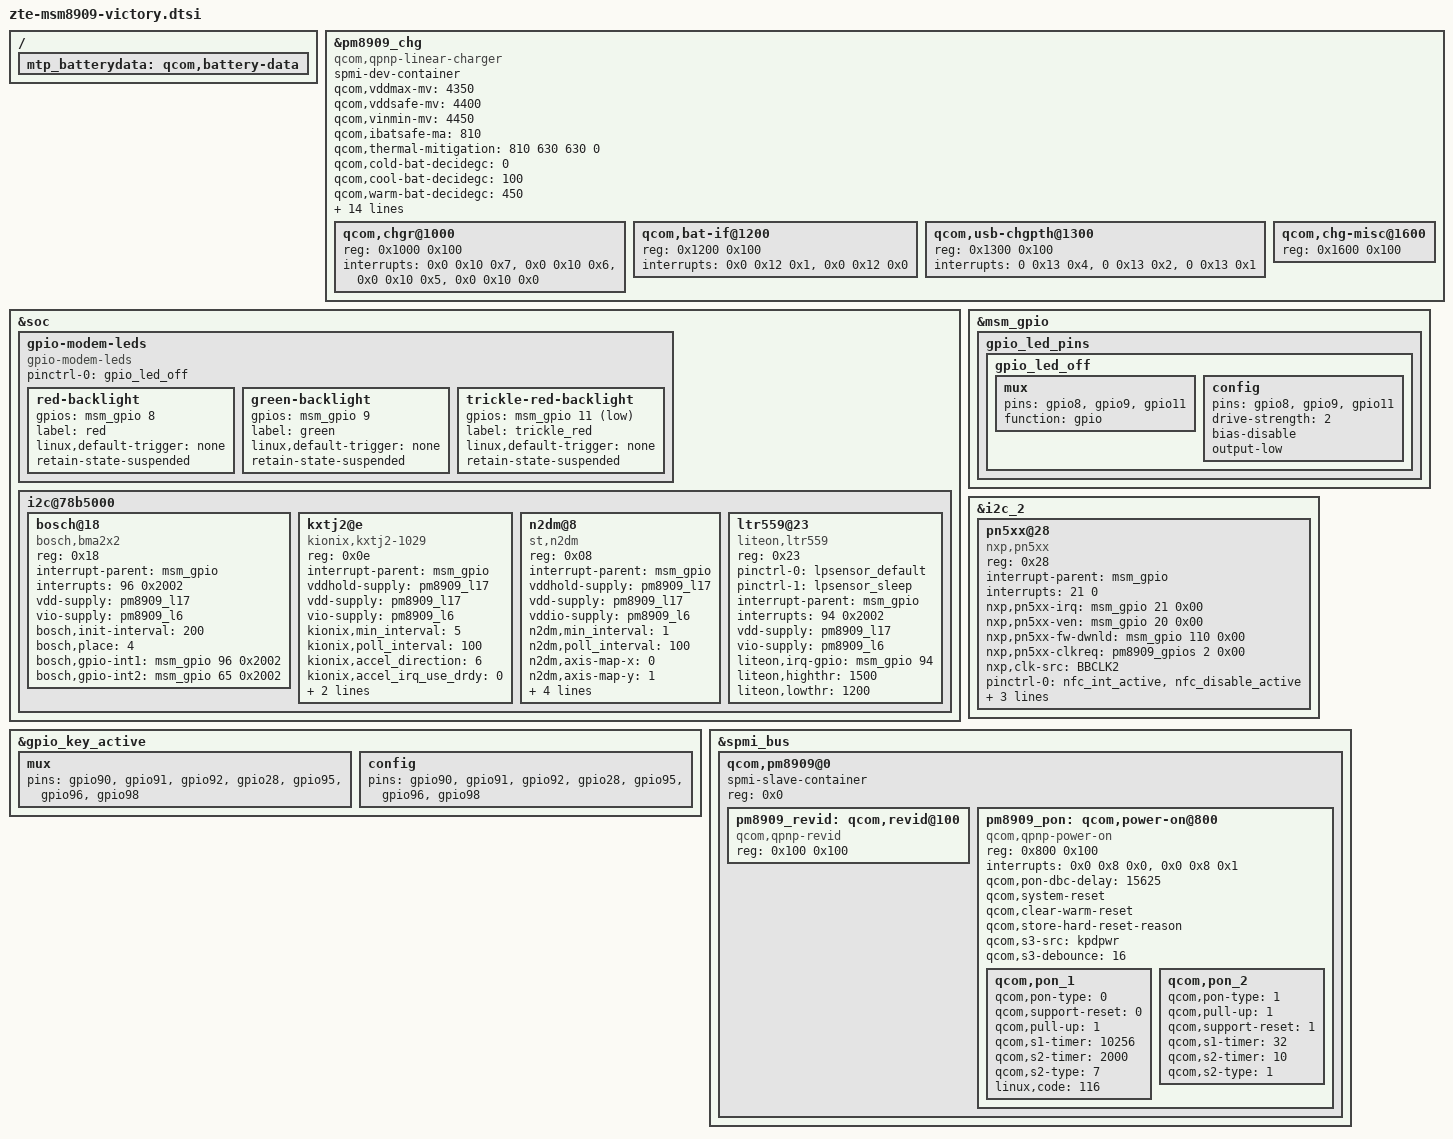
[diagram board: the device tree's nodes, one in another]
#include "touch-key-backlight-victory.dtsi"
#include "zte-victory-dsi-panel-jd9161b-holitech-480p-video.dtsi"
#include "zte-victory-dsi-panel-otm8019a-lianchuang-480p-video.dtsi"
&pm8909_chg {
	spmi-dev-container;
	compatible = "qcom,qpnp-linear-charger";
	#address-cells = <1>;
	#size-cells = <1>;

	qcom,vddmax-mv = <4350>;
	qcom,vddsafe-mv = <4400>;
	qcom,vinmin-mv = <4450>;
	qcom,ibatsafe-ma = <810>;
	qcom,thermal-mitigation = <810 630 630 0>;
	qcom,cold-bat-decidegc = <0>;
	qcom,cool-bat-decidegc = <100>;
	qcom,warm-bat-decidegc = <450>;
	qcom,hot-bat-decidegc = <600>;
	qcom,cool-bat-mv = <4350>;
	qcom,warm-bat-mv = <4100>;
	qcom,ibatmax-warm-ma = <450>;
	qcom,ibatmax-cool-ma = <630>;
	qcom,batt-hot-percentage = <25>;
	qcom,batt-cold-percentage = <80>;
	qcom,tchg-mins = <1536>;
	qcom,resume-soc = <97>;
	qcom,rpull-up-kohm = <100>;
	qcom,vref-batt-id = <1800000>;
	qcom,chg-vadc = <&pm8909_vadc>;
	qcom,chg-adc_tm = <&pm8909_adc_tm>;
	qcom,bpd-detection = "bpd_thm";
	/delete-property/qcom,disable-vbatdet-based-recharge;

	qcom,chgr@1000 {
		reg = <0x1000 0x100>;
		interrupts =	<0x0 0x10 0x7>,
				<0x0 0x10 0x6>,
				<0x0 0x10 0x5>,
				<0x0 0x10 0x0>;
		interrupt-names =	"chg-done",
					"chg-failed",
					"fast-chg-on",
					"vbat-det-lo";
	};

	qcom,bat-if@1200 {
		reg = <0x1200 0x100>;
		interrupts =	<0x0 0x12 0x1>,
				<0x0 0x12 0x0>;
		interrupt-names =	"bat-temp-ok",
					"batt-pres";
	};

	qcom,usb-chgpth@1300 {
		reg = <0x1300 0x100>;
		interrupts =	<0 0x13 0x4>,
				<0 0x13 0x2>,
				<0 0x13 0x1>;
		interrupt-names =	"usb-over-temp",
					"chg-gone",
					"usbin-valid";
	};

	qcom,chg-misc@1600 {
		reg = <0x1600 0x100>;
	};
};

/ {
	mtp_batterydata: qcom,battery-data {
		/delete-node/qcom,palladium-batterydata;
		#include "zte-byd-4v35-2200mah.dtsi"
		#include "zte-bak-4v35-2200mah.dtsi"
	};
};

&soc {
	/*ZTE_MODIFY, add leds gpio conrol, start*/
	gpio-modem-leds {
		compatible = "gpio-modem-leds";
		status = "okay";
		pinctrl-names = "default";
		pinctrl-0 = <&gpio_led_off>;

		red-backlight {
			gpios = <&msm_gpio 8 0>;
			label = "red";
			linux,default-trigger = "none";
			retain-state-suspended;
		};
		green-backlight {
			gpios = <&msm_gpio 9 0>;
			label = "green";
			linux,default-trigger = "none";
			retain-state-suspended;
		};
		trickle-red-backlight {
			gpios = <&msm_gpio 11 1>; /*active low*/
			label = "trickle_red";
			linux,default-trigger = "none";
			retain-state-suspended;
		};
	};
	/*ZTE_MODIFY, add leds gpio conrol, end*/

	i2c@78b5000 { /* BLSP1 QUP1 */
		bosch@18 { /* Accelerometer sensor */
			compatible = "bosch,bma2x2";
			reg = <0x18>;
			interrupt-parent = <&msm_gpio>;
			interrupts = <96 0x2002>;
			vdd-supply = <&pm8909_l17>;
			vio-supply = <&pm8909_l6>;
			bosch,init-interval = <200>;
			bosch,place = <4>;
			bosch,gpio-int1 = <&msm_gpio 96 0x2002>;
			bosch,gpio-int2 = <&msm_gpio 65 0x2002>;
		};

		kxtj2@e {
			compatible = "kionix,kxtj2-1029";
			reg = <0x0e>;
			interrupt-parent = <&msm_gpio>;
			/*interrupts = <96 0x2>;*/
			vddhold-supply = <&pm8909_l17>;
			vdd-supply = <&pm8909_l17>;
			vio-supply = <&pm8909_l6>;
			kionix,min_interval = <5>;
			kionix,poll_interval = <100>;
			kionix,accel_direction = <6>;
			kionix,accel_irq_use_drdy = <0>;
			/*0 is 12BIT,	1 is 8BIT,	2 is 6BIT*/
			kionix,accel_res = <0>;
			/*0 is 2g,	1 is 4g,	2 is 6g,	3 is 8g*/
			kionix,accel_g_range =	<0>;
		};

		n2dm@8 {
			compatible = "st,n2dm";
			reg = <0x08>;
			interrupt-parent = <&msm_gpio>;
			/*interrupts = <96 0x2>;*/
			vddhold-supply = <&pm8909_l17>;
			vdd-supply = <&pm8909_l17>;
			vddio-supply = <&pm8909_l6>;
			n2dm,min_interval = <1>;
			n2dm,poll_interval = <100>;
			n2dm,axis-map-x = <0>;
			n2dm,axis-map-y = <1>;
			n2dm,axis-map-z = <2>;
			n2dm,negate-x;
			/* n2dm,negate-y; */
			n2dm,negate-z;
			/*0 is 2g,	16 is 4g,	32 is 8g,	48 is 16g*/
			n2dm,fs-range = <0>;
		};

		ltr559@23 {
			compatible = "liteon,ltr559";
			reg = <0x23>;
			pinctrl-names = "lpsensor_default", "lpsensor_sleep";
			pinctrl-0 = <&lpsensor_default>;
			pinctrl-1 = <&lpsensor_sleep>;
			interrupt-parent = <&msm_gpio>;
			interrupts = <94 0x2002>;
			vdd-supply = <&pm8909_l17>;
			vio-supply = <&pm8909_l6>;
			liteon,irq-gpio = <&msm_gpio 94 0x2002>;
			liteon,highthr = <1500>;
			liteon,lowthr = <1200>;
		};

	};
};
&msm_gpio {
	/*ZTE_MODIFY, add leds gpio conrol, start*/
	gpio_led_pins {
		gpio_led_off: gpio_led_off {
			mux {
				pins = "gpio8", "gpio9", "gpio11";
				function = "gpio";
			};

			config {
				pins = "gpio8", "gpio9", "gpio11";
				drive-strength = <2>;
				bias-disable;
				output-low;
			};
		};
	};
	/*ZTE_MODIFY, add leds gpio conrol, end*/
};
&i2c_2 {
	/delete-node/nq@28;
};

&i2c_2 {
	pn5xx@28{
		compatible = "nxp,pn5xx";
		reg = <0x28>;
		interrupt-parent = <&msm_gpio>;
		interrupts = <21 0>;
		nxp,pn5xx-irq = <&msm_gpio 21 0x00>;
		nxp,pn5xx-ven = <&msm_gpio 20 0x00>;
		nxp,pn5xx-fw-dwnld = <&msm_gpio 110 0x00>;
		//nxp,pn5xx-ese-pwr = <&tlmm 141 0x00>;
		//nxp,pn5xx-swp2-pwr = <&tlmm129 0x00>;
		//nxp,int_active_low = <0>;
		nxp,pn5xx-clkreq = <&pm8909_gpios 2 0x00>;
		nxp,clk-src = "BBCLK2";
		interrupt-names = "nfc_irq";
		pinctrl-names = "nfc_active","nfc_suspend";
		pinctrl-0 = <&nfc_int_active &nfc_disable_active>;
		pinctrl-1 = <&nfc_int_suspend &nfc_disable_suspend>;
		clocks = <&clock_rpm clk_bb_clk2_pin>;
		clock-names = "bb_clk2";
	};
};

&gpio_key_active {
	mux {
		pins = "gpio90", "gpio91", "gpio92", "gpio28", "gpio95",
		"gpio96", "gpio98";

	};

	config {
		pins = "gpio90", "gpio91", "gpio92", "gpio28", "gpio95",
		"gpio96", "gpio98";
	};
};

&spmi_bus {

	qcom,pm8909@0 {
		spmi-slave-container;
		reg = <0x0>;
		#address-cells = <1>;
		#size-cells = <1>;

		pm8909_revid: qcom,revid@100 {
			compatible = "qcom,qpnp-revid";
			reg = <0x100 0x100>;
		};

		pm8909_pon: qcom,power-on@800 {
			compatible = "qcom,qpnp-power-on";
			reg = <0x800 0x100>;
			interrupts = <0x0 0x8 0x0>,
				     <0x0 0x8 0x1>;
			interrupt-names = "kpdpwr", "resin";
			qcom,pon-dbc-delay = <15625>;
			qcom,system-reset;
			qcom,clear-warm-reset;
			qcom,store-hard-reset-reason;
			qcom,s3-src = "kpdpwr";
			qcom,s3-debounce = <16>;

			qcom,pon_1 {
				qcom,pon-type = <0>;
				qcom,support-reset = <0>;
				qcom,pull-up = <1>;
				qcom,s1-timer = <10256>;
				qcom,s2-timer = <2000>;
				qcom,s2-type = <7>;
				linux,code = <116>;
			};

			qcom,pon_2 {
				qcom,pon-type = <1>;
				qcom,pull-up = <1>;
				/*linux,code = <114>;*/
				qcom,support-reset = <1>;
				qcom,s1-timer = <32>;
				qcom,s2-timer = <10>;
				qcom,s2-type = <1>;
			};
		};
	};
};
